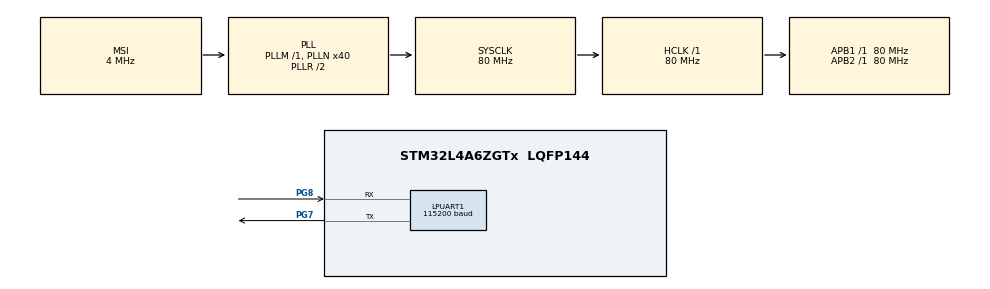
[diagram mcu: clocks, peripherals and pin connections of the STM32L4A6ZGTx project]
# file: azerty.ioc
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Dma.LPUART_RX.0.Direction=DMA_PERIPH_TO_MEMORY
Dma.LPUART_RX.0.Instance=DMA2_Channel7
Dma.LPUART_RX.0.MemDataAlignment=DMA_MDATAALIGN_BYTE
Dma.LPUART_RX.0.MemInc=DMA_MINC_ENABLE
Dma.LPUART_RX.0.Mode=DMA_CIRCULAR
Dma.LPUART_RX.0.PeriphDataAlignment=DMA_PDATAALIGN_BYTE
Dma.LPUART_RX.0.PeriphInc=DMA_PINC_DISABLE
Dma.LPUART_RX.0.Priority=DMA_PRIORITY_VERY_HIGH
Dma.Request0=LPUART_RX
FREERTOS.Tasks01=defaultTask,0,128,StartDefaultTask,Default,NULL
LPUART1.BaudRate=115200
LPUART1.WordLength=UART_WORDLENGTH_8B
Mcu.Family=STM32L4
Mcu.Name=STM32L4A6ZGTx
Mcu.Package=LQFP144
NVIC.DMA2_Channel7_IRQn=true\:5\:0\:false\:false\:true\:true\:false\:true
NVIC.LPUART1_IRQn=true\:5\:0\:false\:false\:true\:true\:true\:true
NVIC.PriorityGroup=NVIC_PRIORITYGROUP_4
NVIC.TIM6_DAC_IRQn=true\:0\:0\:false\:false\:true\:false\:false\:true
NVIC.TimeBase=TIM6_DAC_IRQn
NVIC.TimeBaseIP=TIM6
PG7.Mode=Asynchronous
PG7.Signal=LPUART1_TX
PG8.Mode=Asynchronous
PG8.Signal=LPUART1_RX
ProjectManager.HeapSize=0x200
ProjectManager.StackSize=0x400
ProjectManager.TargetToolchain=EWARM V8.32
RCC.AHBFreq_Value=80000000
RCC.APB1Freq_Value=80000000
RCC.APB1TimFreq_Value=80000000
RCC.APB2Freq_Value=80000000
RCC.APB2TimFreq_Value=80000000
RCC.CortexFreq_Value=80000000
RCC.HCLKFreq_Value=80000000
RCC.HSE_VALUE=8000000
RCC.HSI48_VALUE=48000000
RCC.HSI_VALUE=16000000
RCC.LSE_VALUE=32768
RCC.MSI_VALUE=4000000
RCC.PLLN=40
RCC.SYSCLKFreq_VALUE=80000000
RCC.SYSCLKSource=RCC_SYSCLKSOURCE_PLLCLK
RCC.VCOOutputFreq_Value=160000000
VP_FREERTOS_VS_CMSIS_V1.Mode=CMSIS_V1
VP_SYS_VS_tim6.Mode=TIM6
VP_TIM7_VS_ClockSourceINT.Mode=Enable_Timer
board=custom

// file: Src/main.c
/* USER CODE BEGIN Header */
/**
  ******************************************************************************
  * @file           : main.c
  * @brief          : Main program body
  ******************************************************************************
  * @attention
  *
  * <h2><center>&copy; Copyright (c) 2019 STMicroelectronics.
  * All rights reserved.</center></h2>
  *
  * This software component is licensed by ST under Ultimate Liberty license
  * SLA0044, the "License"; You may not use this file except in compliance with
  * the License. You may obtain a copy of the License at:
  *                             www.st.com/SLA0044
  *
  ******************************************************************************
  */
/* USER CODE END Header */

#include "main.h"

/* USER CODE BEGIN PD */
#define RxData_Size       32
#define TIM_Data_Size     26
#define Queue_Size         1
#define Start_Data_Size    6
#define Stop_Data_Size     5
#define Counter_Max       255

#define Start_Data         "start\n"
#define Stop_Data          "stop\n"
#define CR_LF             "\r\n"
#define LF                  '\n'
#define CR                  '\r'
/* USER CODE END PD */

UART_HandleTypeDef hlpuart1;
DMA_HandleTypeDef hdma_lpuart_rx;

TIM_HandleTypeDef htim7;

osThreadId defaultTaskHandle;
/* USER CODE BEGIN PV */

uint8_t Rx_Data = 0;
uint8_t Rx_Queue_Message[RxData_Size];
uint8_t Timer_Data[TIM_Data_Size] = "\r\nTimer Period Elapsed \r\n";
uint8_t uTimerCounter = 0;

TaskHandle_t xHandle = NULL;
QueueHandle_t xQueue = NULL;
/* USER CODE END PV */

void SystemClock_Config(void);
static void MX_GPIO_Init(void);
static void MX_LPUART1_UART_Init(void);
static void MX_DMA_Init(void);
static void MX_TIM7_Init(void);

/* USER CODE BEGIN PFP */
static void vTask1(void *pvParameters);
/* USER CODE END PFP */

int main(void)
{

  /* MCU Configuration--------------------------------------------------------*/

  /* Reset of all peripherals, Initializes the Flash interface and the Systick. */
  HAL_Init();

  /* Configure the system clock */
  SystemClock_Config();

  /* Initialize all configured peripherals */
  MX_GPIO_Init();
  MX_LPUART1_UART_Init();
  MX_DMA_Init();
  MX_TIM7_Init();
  /* USER CODE BEGIN 2 */

  HAL_UART_Receive_IT(&hlpuart1, &Rx_Data, 1);
  /* USER CODE END 2 */

  /* USER CODE BEGIN RTOS_QUEUES */
  xQueue = xQueueCreate(Queue_Size, sizeof(uint8_t));
  if (xQueue == NULL)
  {
    Error_Handler();
  }
  /* USER CODE END RTOS_QUEUES */

  /* Create the thread(s) */
  /* definition and creation of defaultTask */

  /* USER CODE BEGIN RTOS_THREADS */
  /* add threads, ... */
  xTaskCreate(vTask1, "Task 1", 128, NULL, osPriorityRealtime, &xHandle);
  /* USER CODE END RTOS_THREADS */

  /* Start scheduler */

  /* We should never get here as control is now taken by the scheduler */

  /* Infinite loop */
  /* USER CODE BEGIN WHILE */
  vTaskStartScheduler();
  while (1)
  {
    /* USER CODE END WHILE */

  }
}

void SystemClock_Config(void)
{
  RCC_OscInitTypeDef RCC_OscInitStruct = {0};
  RCC_ClkInitTypeDef RCC_ClkInitStruct = {0};
  RCC_PeriphCLKInitTypeDef PeriphClkInit = {0};

  /** Initializes the CPU, AHB and APB busses clocks
  */
  RCC_OscInitStruct.OscillatorType = RCC_OSCILLATORTYPE_MSI;
  RCC_OscInitStruct.MSIState = RCC_MSI_ON;
  RCC_OscInitStruct.MSICalibrationValue = 0;
  RCC_OscInitStruct.MSIClockRange = RCC_MSIRANGE_6;
  RCC_OscInitStruct.PLL.PLLState = RCC_PLL_ON;
  RCC_OscInitStruct.PLL.PLLSource = RCC_PLLSOURCE_MSI;
  RCC_OscInitStruct.PLL.PLLM = 1;
  RCC_OscInitStruct.PLL.PLLN = 40;
  RCC_OscInitStruct.PLL.PLLP = RCC_PLLP_DIV2;
  RCC_OscInitStruct.PLL.PLLQ = RCC_PLLQ_DIV2;
  RCC_OscInitStruct.PLL.PLLR = RCC_PLLR_DIV2;
  if (HAL_RCC_OscConfig(&RCC_OscInitStruct) != HAL_OK)
  {
    Error_Handler();
  }
  /** Initializes the CPU, AHB and APB busses clocks
  */
  RCC_ClkInitStruct.ClockType = RCC_CLOCKTYPE_HCLK|RCC_CLOCKTYPE_SYSCLK
                              |RCC_CLOCKTYPE_PCLK1|RCC_CLOCKTYPE_PCLK2;
  RCC_ClkInitStruct.SYSCLKSource = RCC_SYSCLKSOURCE_PLLCLK;
  RCC_ClkInitStruct.AHBCLKDivider = RCC_SYSCLK_DIV1;
  RCC_ClkInitStruct.APB1CLKDivider = RCC_HCLK_DIV1;
  RCC_ClkInitStruct.APB2CLKDivider = RCC_HCLK_DIV1;

  if (HAL_RCC_ClockConfig(&RCC_ClkInitStruct, FLASH_LATENCY_4) != HAL_OK)
  {
    Error_Handler();
  }
  PeriphClkInit.PeriphClockSelection = RCC_PERIPHCLK_LPUART1;
  PeriphClkInit.Lpuart1ClockSelection = RCC_LPUART1CLKSOURCE_PCLK1;
  if (HAL_RCCEx_PeriphCLKConfig(&PeriphClkInit) != HAL_OK)
  {
    Error_Handler();
  }
  /** Configure the main internal regulator output voltage
  */
  if (HAL_PWREx_ControlVoltageScaling(PWR_REGULATOR_VOLTAGE_SCALE1) != HAL_OK)
  {
    Error_Handler();
  }
}

static void MX_LPUART1_UART_Init(void)
{

  hlpuart1.Instance = LPUART1;
  hlpuart1.Init.BaudRate = 9600;
  hlpuart1.Init.WordLength = UART_WORDLENGTH_8B;
  hlpuart1.Init.StopBits = UART_STOPBITS_1;
  hlpuart1.Init.Parity = UART_PARITY_NONE;
  hlpuart1.Init.Mode = UART_MODE_TX_RX;
  hlpuart1.Init.HwFlowCtl = UART_HWCONTROL_NONE;
  hlpuart1.Init.OneBitSampling = UART_ONE_BIT_SAMPLE_DISABLE;
  hlpuart1.AdvancedInit.AdvFeatureInit = UART_ADVFEATURE_NO_INIT;
  if (HAL_UART_Init(&hlpuart1) != HAL_OK)
  {
    Error_Handler();
  }

}

static void MX_TIM7_Init(void)
{

  TIM_MasterConfigTypeDef sMasterConfig = {0};

  htim7.Instance = TIM7;
  htim7.Init.Prescaler = 79999;
  htim7.Init.CounterMode = TIM_COUNTERMODE_UP;
  htim7.Init.Period = 9999;
  htim7.Init.AutoReloadPreload = TIM_AUTORELOAD_PRELOAD_DISABLE;
  if (HAL_TIM_Base_Init(&htim7) != HAL_OK)
  {
    Error_Handler();
  }
  sMasterConfig.MasterOutputTrigger = TIM_TRGO_RESET;
  sMasterConfig.MasterSlaveMode = TIM_MASTERSLAVEMODE_DISABLE;
  if (HAL_TIMEx_MasterConfigSynchronization(&htim7, &sMasterConfig) != HAL_OK)
  {
    Error_Handler();
  }

}

static void MX_DMA_Init(void)
{

  /* DMA controller clock enable */
  __HAL_RCC_DMA2_CLK_ENABLE();

  /* DMA interrupt init */
  /* DMA2_Channel7_IRQn interrupt configuration */
  HAL_NVIC_SetPriority(DMA2_Channel7_IRQn, 5, 0);
  HAL_NVIC_EnableIRQ(DMA2_Channel7_IRQn);

}

static void MX_GPIO_Init(void)
{

  /* GPIO Ports Clock Enable */
  __HAL_RCC_GPIOG_CLK_ENABLE();
  HAL_PWREx_EnableVddIO2();

}

/* USER CODE BEGIN 4 */
void vTask1(void *pvParameters)
{
  // const TickType_t xDelayInMs = pdMS_TO_TICKS(100);
  uint8_t index = 0;

  for(;;)
  {
    if(xQueueReceive(xQueue, &Rx_Data, 0))
    {
      /* Perform any processing necessitated by the interrupt. */
      Rx_Queue_Message[index] = Rx_Data;
      if (Rx_Data == LF)
      {
        // Echo back recieved data
        HAL_UART_Transmit(&hlpuart1, Rx_Queue_Message, index, 100);
        if (memcmp(Rx_Queue_Message, Start_Data, Start_Data_Size) == 0)
        {
          // Start timer
          if (HAL_TIM_Base_Start_IT(&htim7) == HAL_OK)
          {
            HAL_UART_Transmit_IT(&hlpuart1, "\r\nStarting Timer\r\n", 18);
          }
        }
        else if (memcmp(Rx_Queue_Message, Stop_Data, Stop_Data_Size) == 0)
        {
          // Stop timer
          if (HAL_TIM_Base_Stop_IT(&htim7) == HAL_OK)
          {
            HAL_UART_Transmit_IT(&hlpuart1, "\r\nStopping Timer\r\n", 18);
            uTimerCounter = 0;
          }
        }
        memset(Rx_Queue_Message, 0, RxData_Size);
        index = 0;
      }
      else
      {
        index++;
      }
    }
    // vTaskDelay(xDelayInMs);
  }
}

void HAL_UART_RxCpltCallback(UART_HandleTypeDef *huart)
{
  if (xQueueSendFromISR(xQueue, &Rx_Data, NULL))
  {
    // Sending 1 byte from ISR to Queue
  }
  else
  {
    // Could not send 1 byte from ISR to Queue
  }
  HAL_UART_Receive_IT(&hlpuart1, &Rx_Data, 1);
}

/* USER CODE END 4 */

void HAL_TIM_PeriodElapsedCallback(TIM_HandleTypeDef *htim)
{
  if (htim->Instance == TIM6) {
    HAL_IncTick();
  }
  else if (htim->Instance == TIM7)
  {
    // TODO: Move this process OUT of the Timer Interrupt Callback
    snprintf((char *) Timer_Data+23, TIM_Data_Size, "%d", uTimerCounter);
    if (HAL_UART_Transmit_IT(&hlpuart1, Timer_Data, TIM_Data_Size) == HAL_OK)
    {
      uTimerCounter++;
    }
  }
}

void Error_Handler(void)
{
  /* USER CODE BEGIN Error_Handler_Debug */
  /* User can add his own implementation to report the HAL error return state */
  while(1);
  /* USER CODE END Error_Handler_Debug */
}

/************************ (C) COPYRIGHT STMicroelectronics *****END OF FILE****/
